# DA1470x register map
Vendor: Dialog; Series: DA1470x; File version: 1.2
CPU: CM33 r0p2, little endian, MPU, FPU, DSP, VTOR, 4 interrupt priority bits
Registers are 32-bit, read-write, reset 0x0 unless marked. A register's access mark holds for its fields unless they carry their own. Offsets are from the block's base; [hi:lo] are bit positions; 'fields as' and 'values as' point back to an identical list.

## CRG_GPU — CRG_GPU registers
Base 0x51001000
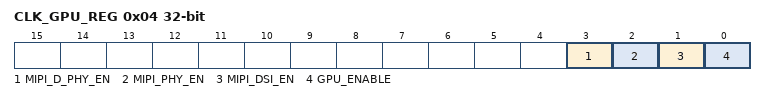
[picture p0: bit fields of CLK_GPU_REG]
0x04 CLK_GPU_REG — Control register for clocks in PD_GPU
  [3] MIPI_D_PHY_EN, [2] MIPI_PHY_EN, [1] MIPI_DSI_EN, [0] GPU_ENABLE

## CRG_SNC — CRG_SNC registers
Base 0x50020900
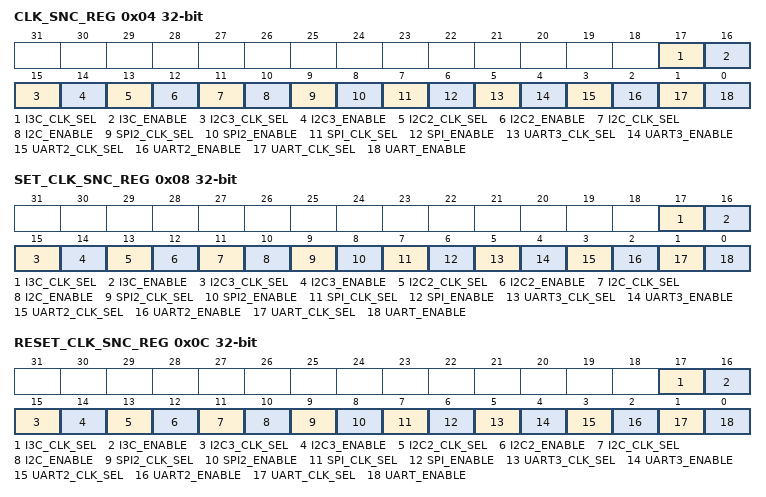
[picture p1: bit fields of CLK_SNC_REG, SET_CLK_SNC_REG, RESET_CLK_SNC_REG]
0x04 CLK_SNC_REG — Peripheral divider register
  [17] I3C_CLK_SEL — Selects the clock source 1 = DIV1 clock 0 = DIVN clock
  [16] I3C_ENABLE — Enables the clock
  [15] I2C3_CLK_SEL — Selects the clock source 1 = DIV1 clock 0 = DIVN clock
  [14] I2C3_ENABLE — Enables the clock
  [13] I2C2_CLK_SEL — Selects the clock source 1 = DIV1 clock 0 = DIVN clock
  [12] I2C2_ENABLE — Enables the clock
  [11] I2C_CLK_SEL — Selects the clock source 1 = DIV1 clock 0 = DIVN clock
  [10] I2C_ENABLE — Enables the clock
  [9] SPI2_CLK_SEL — Selects the clock source 1 = DIV1 clock 0 = DIVN clock
  [8] SPI2_ENABLE — Enables the clock
  [7] SPI_CLK_SEL — Selects the clock source 1 = DIV1 clock 0 = DIVN clock
  [6] SPI_ENABLE — Enables the clock
  [5] UART3_CLK_SEL — Selects the clock source 1 = DIV1 clock 0 = DIVN clock
  [4] UART3_ENABLE — Enables the clock
  [3] UART2_CLK_SEL — Selects the clock source 1 = DIV1 clock 0 = DIVN clock
  [2] UART2_ENABLE — Enables the clock
  [1] UART_CLK_SEL — Selects the clock source 1 = DIV1 clock 0 = DIVN clock
  [0] UART_ENABLE — Enables the clock
0x08 SET_CLK_SNC_REG — Peripheral divider register SET register. Reads back 0x0000
  [17] I3C_CLK_SEL — Selects the clock source 1 = DIV1 clock 0 = DIVN clock
  [16] I3C_ENABLE rw-once — Enables the clock
  [15] I2C3_CLK_SEL — Selects the clock source 1 = DIV1 clock 0 = DIVN clock
  [14] I2C3_ENABLE — Enables the clock
  [13] I2C2_CLK_SEL rw-once — Selects the clock source 1 = DIV1 clock 0 = DIVN clock
  [12] I2C2_ENABLE rw-once — Enables the clock
  [11] I2C_CLK_SEL rw-once — Selects the clock source 1 = DIV1 clock 0 = DIVN clock
  [10] I2C_ENABLE rw-once — Enables the clock
  [9] SPI2_CLK_SEL rw-once — Selects the clock source 1 = DIV1 clock 0 = DIVN clock
  [8] SPI2_ENABLE rw-once — Enables the clock
  [7] SPI_CLK_SEL rw-once — Selects the clock source 1 = DIV1 clock 0 = DIVN clock
  [6] SPI_ENABLE rw-once — Enables the clock
  [5] UART3_CLK_SEL rw-once — Selects the clock source 1 = DIV1 clock 0 = DIVN clock
  [4] UART3_ENABLE rw-once — Enables the clock
  [3] UART2_CLK_SEL rw-once — Selects the clock source 1 = DIV1 clock 0 = DIVN clock
  [2] UART2_ENABLE rw-once — Enables the clock
  [1] UART_CLK_SEL rw-once — Selects the clock source 1 = DIV1 clock 0 = DIVN clock
  [0] UART_ENABLE rw-once — Enables the clock
0x0C RESET_CLK_SNC_REG — Peripheral divider register RESET register. Reads back 0x0000
  fields as CLK_SNC_REG

## CRG_SYS — CRG_SYS registers
Base 0x50040400
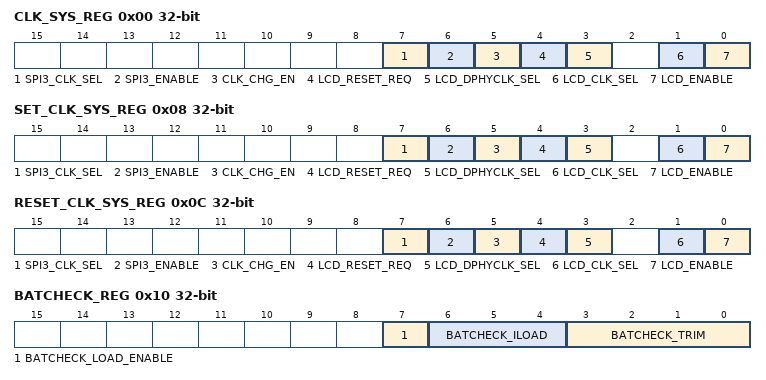
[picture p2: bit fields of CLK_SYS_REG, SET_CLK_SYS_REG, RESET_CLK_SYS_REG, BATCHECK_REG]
0x00 CLK_SYS_REG — Peripheral divider register
  [7] SPI3_CLK_SEL — Selects the clock source 1 = DIV1 clock 0 = DIVN clock
  [6] SPI3_ENABLE — Enables the clock
  [5] CLK_CHG_EN — Enables the clocks for the charger FSM block
  [4] LCD_RESET_REQ — Generates a SW reset towards the LCD controller.
  [3] LCD_DPHYCLK_SEL — This bitfield selects the clock source for the LCD controller. This bit may not be changed while LCDC is active. 0: source as selected by LCD_SYSCLK_DIV2 bit 1: DPHY byte clock
  [1] LCD_CLK_SEL — Selects the clock source 1 = DIV1 clock 0 = DIVN clock
  [0] LCD_ENABLE — Enables the clock
0x08 SET_CLK_SYS_REG — Peripheral divider SET register
  fields as CLK_SYS_REG
0x0C RESET_CLK_SYS_REG — Peripheral divider RESET register
  fields as CLK_SYS_REG
0x10 BATCHECK_REG
  [7] BATCHECK_LOAD_ENABLE — Enable a current load on the battery.
  [6:4] BATCHECK_ILOAD — Set the current load to (ILOAD+1) mA.
  [3:0] BATCHECK_TRIM — Trim the current load with steps of 2.7% from -19.1% to +19.1%. 0: +0.0% , 8: -0% 1: +2.7% , 9: -2.7% 2: +5.5% , 10: -5.5% 3: +8.2% , 11: -8.2% 4: +10.9% , 12: -10.9% 5: +13.6% , 13: -13.6% 6: +16.4% , 14: -16.4% 7: +19.1% , 15: -19.1%
